# ATmega162 device description
Architecture: AVR8; Family: megaAVR
Registers are 8-bit, access not given, no defined reset value unless marked. A register's access mark holds for its fields unless they carry their own. Offsets are from the block's base; [hi:lo] are bit positions.

## TC2 (TC8_ASYNC module) — Timer/Counter, 8-bit Async
Instances: TC2 0x00
0x42 OCR2 — Output Compare Register
0x43 TCNT2 — Timer/Counter Register
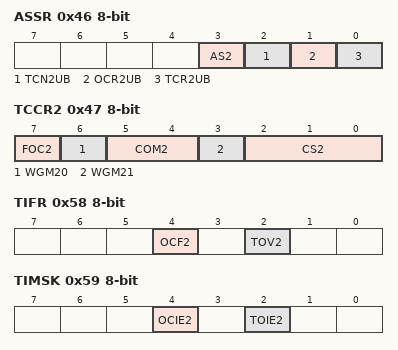
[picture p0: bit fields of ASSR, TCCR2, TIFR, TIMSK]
0x46 ASSR — Asynchronous Status Register
  [3] AS2 — Asynchronous Timer 2
  [2] TCN2UB — Timer/Counter2 Update Busy
  [1] OCR2UB — Output Compare Register2 Update Busy
  [0] TCR2UB — Timer/Counter Control Register2 Update Busy
0x47 TCCR2 — Timer/Counter Control Register
  [7] FOC2 — Force Output Compare
  [6] WGM20 — Pulse Width Modulator Select Bit 0
    0=NORMAL; 2=PWM_PHASE_CORRECT; 1=CTC; 3=FAST_PWM
  [5:4] COM2 — Compare Match Output Mode
  [3] WGM21 — Pulse Width Modulator Select Bit 1
  [2:0] CS2 — Clock Select
    0=NO_CLOCK_SOURCE_STOPPED; 1=RUNNING_NO_PRESCALING; 2=RUNNING_CLK_8; 3=RUNNING_CLK_32; 4=RUNNING_CLK_64; 5=RUNNING_CLK_128; 6=RUNNING_CLK_256; 7=RUNNING_CLK_1024
0x58 TIFR — Timer/Counter Interrupt Flag Register
  [4] OCF2 — Output Compare Flag 2
  [2] TOV2 — Timer/Counter2 Overflow Flag
0x59 TIMSK — Timer/Counter Interrupt Mask Register
  [4] OCIE2 — Timer/Counter2 Output Compare Match Interrupt Enable
  [2] TOIE2 — Timer/Counter2 Overflow Interrupt Enable

## AC — Analog Comparator
Instances: AC 0x00
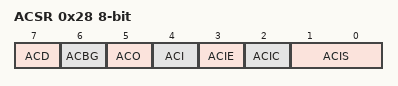
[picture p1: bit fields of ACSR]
0x28 ACSR — Analog Comparator Control And Status Register
  [7] ACD — Analog Comparator Disable
  [6] ACBG — Analog Comparator Bandgap Select
  [5] ACO — Analog Compare Output
  [4] ACI — Analog Comparator Interrupt Flag
  [3] ACIE — Analog Comparator Interrupt Enable
  [2] ACIC — Analog Comparator Input Capture Enable
  [1:0] ACIS — Analog Comparator Interrupt Mode Select bits
    0=INTERRUPT_ON_TOGGLE; 2=INTERRUPT_ON_FALLING_EDGE; 3=INTERRUPT_ON_RISING_EDGE

## USART0 — USART
Instances: USART0 0x00
0x29 UBRR0L — USART Baud Rate Register Low Byte
  [7:0] UBRR0 — USART Baud Rate Register Low bits
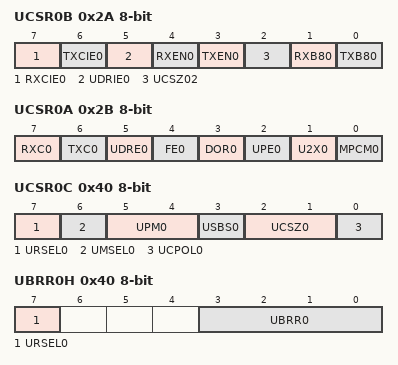
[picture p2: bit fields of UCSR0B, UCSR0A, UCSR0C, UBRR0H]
0x2A UCSR0B — USART Control and Status Register B
  [7] RXCIE0 — RX Complete Interrupt Enable
  [6] TXCIE0 — TX Complete Interrupt Enable
  [5] UDRIE0 — USART Data register Empty Interrupt Enable
  [4] RXEN0 — Receiver Enable
  [3] TXEN0 — Transmitter Enable
  [2] UCSZ02 — Character Size
  [1] RXB80 — Receive Data Bit 8
  [0] TXB80 — Transmit Data Bit 8
0x2B UCSR0A — USART Control and Status Register A
  [7] RXC0 ro — USART Receive Complete
  [6] TXC0 — USART Transmit Complete
  [5] UDRE0 ro — USART Data Register Empty
  [4] FE0 ro — Framing Error
  [3] DOR0 ro — Data overRun
  [2] UPE0 ro — Parity Error
  [1] U2X0 — Double the USART transmission speed
  [0] MPCM0 — Multi-processor Communication Mode
0x2C UDR0 — USART I/O Data Register
0x40 UCSR0C — USART Control and Status Register C
  [7] URSEL0 — Register Select
  [6] UMSEL0 — USART Mode Select
    0=ASYNCHRONOUS_OPERATION; 1=SYNCHRONOUS_OPERATION
  [5:4] UPM0 — Parity Mode Bits
    0=DISABLED; 2=ENABLED_EVEN_PARITY; 3=ENABLED_ODD_PARITY
  [3] USBS0 — Stop Bit Select
    0=1_BIT; 1=2_BIT
  [2:1] UCSZ0 — Character Size
  [0] UCPOL0 — Clock Polarity
0x40 UBRR0H — USART Baud Rate Register High Byte
  [7] URSEL0 — Register Select
  [3:0] UBRR0 (bit 8 of the value upward) — USART Baud Rate Register High bits

## USART1 — USART
Instances: USART1 0x00
0x20 UBRR1L — USART Baud Rate Register Low Byte
  [7:0] UBRR1 — USART Baud Rate Register Low bits
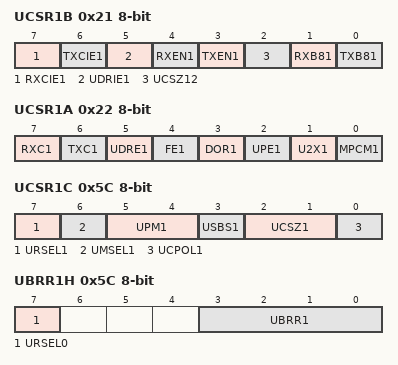
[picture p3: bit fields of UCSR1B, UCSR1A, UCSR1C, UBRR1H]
0x21 UCSR1B — USART Control and Status Register B
  [7] RXCIE1 — RX Complete Interrupt Enable
  [6] TXCIE1 — TX Complete Interrupt Enable
  [5] UDRIE1 — USART Data register Empty Interrupt Enable
  [4] RXEN1 — Receiver Enable
  [3] TXEN1 — Transmitter Enable
  [2] UCSZ12 — Character Size
  [1] RXB81 — Receive Data Bit 8
  [0] TXB81 — Transmit Data Bit 8
0x22 UCSR1A — USART Control and Status Register A
  [7] RXC1 — USART Receive Complete
  [6] TXC1 — USART Transmit Complete
  [5] UDRE1 — USART Data Register Empty
  [4] FE1 — Framing Error
  [3] DOR1 — Data overRun
  [2] UPE1 — Parity Error
  [1] U2X1 — Double the USART transmission speed
  [0] MPCM1 — Multi-processor Communication Mode
0x23 UDR1 — USART I/O Data Register
0x5C UCSR1C — USART Control and Status Register C
  [7] URSEL1 — Register Select
  [6] UMSEL1 — USART Mode Select
    0=ASYNCHRONOUS_OPERATION; 1=SYNCHRONOUS_OPERATION
  [5:4] UPM1 — Parity Mode Bits
    0=DISABLED; 2=ENABLED_EVEN_PARITY; 3=ENABLED_ODD_PARITY
  [3] USBS1 — Stop Bit Select
    0=1_BIT; 1=2_BIT
  [2:1] UCSZ1 — Character Size
  [0] UCPOL1 — Clock Polarity
0x5C UBRR1H — USART Baud Rate Register High Byte
  [7] URSEL0 — Register Select
  [3:0] UBRR1 (bit 8 of the value upward) — USART Baud Rate Register High bits
